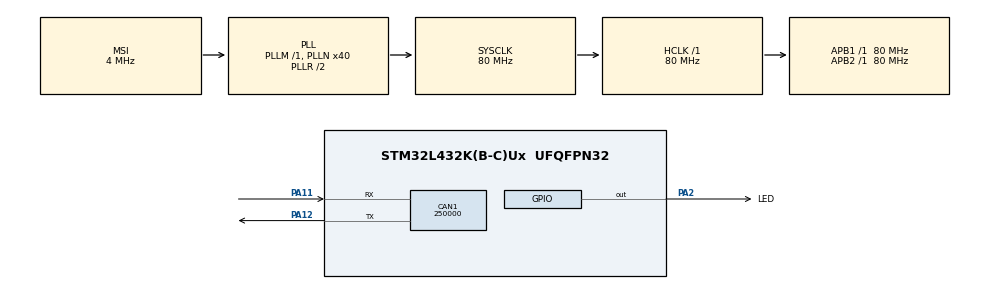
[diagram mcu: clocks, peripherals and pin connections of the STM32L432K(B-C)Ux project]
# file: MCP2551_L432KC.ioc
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CAN1.BS1=CAN_BS1_13TQ
CAN1.BS2=CAN_BS2_6TQ
CAN1.CalculateBaudRate=250000
CAN1.CalculateTimeBit=4000
CAN1.CalculateTimeQuantum=200.0
Mcu.Family=STM32L4
Mcu.Name=STM32L432K(B-C)Ux
Mcu.Package=UFQFPN32
NVIC.CAN1_RX0_IRQn=true\:0\:0\:false\:false\:true\:true\:true\:true
NVIC.PriorityGroup=NVIC_PRIORITYGROUP_4
PA0.Mode=HSE-External-Clock-Source-for-LittleOrca
PA0.Signal=RCC_CK_IN
PA11.Mode=CAN_Activate
PA11.Signal=CAN1_RX
PA12.Mode=CAN_Activate
PA12.Signal=CAN1_TX
PA13\ (JTMS-SWDIO).Mode=Serial_Wire
PA13\ (JTMS-SWDIO).Signal=SYS_JTMS-SWDIO
PA14\ (JTCK-SWCLK).Mode=Serial_Wire
PA14\ (JTCK-SWCLK).Signal=SYS_JTCK-SWCLK
PA2.GPIO_Label=LED
PA2.Signal=GPIO_Output
ProjectManager.HeapSize=0x200
ProjectManager.StackSize=0x400
ProjectManager.TargetToolchain=STM32CubeIDE
RCC.AHBFreq_Value=80000000
RCC.APB1Freq_Value=80000000
RCC.APB1TimFreq_Value=80000000
RCC.APB2Freq_Value=80000000
RCC.APB2TimFreq_Value=80000000
RCC.CortexFreq_Value=80000000
RCC.HCLKFreq_Value=80000000
RCC.HSE_VALUE=8000000
RCC.HSI48_VALUE=48000000
RCC.HSI_VALUE=16000000
RCC.LSE_VALUE=32768
RCC.MSI_VALUE=4000000
RCC.PLLN=40
RCC.SYSCLKFreq_VALUE=80000000
RCC.SYSCLKSource=RCC_SYSCLKSOURCE_PLLCLK
RCC.VCOOutputFreq_Value=160000000
board=custom

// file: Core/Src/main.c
/* USER CODE BEGIN Header */
/**
  ******************************************************************************
  * @file           : main.c
  * @brief          : Main program body
  ******************************************************************************
  * @attention
  *
  * Copyright (c) 2024 STMicroelectronics.
  * All rights reserved.
  *
  * This software is licensed under terms that can be found in the LICENSE file
  * in the root directory of this software component.
  * If no LICENSE file comes with this software, it is provided AS-IS.
  *
  ******************************************************************************
  */
/* USER CODE END Header */
#include "main.h"

CAN_HandleTypeDef hcan1;

/* USER CODE BEGIN PV */
CAN_TxHeaderTypeDef   TxHeader; // CAN Header
uint8_t               TxData[8]; // CAN Data
uint32_t              TxMailbox; // track id Transmission mailbox

CAN_RxHeaderTypeDef   RxHeader;
uint8_t               RxData[8];
uint8_t data_avail;

/* USER CODE END PV */

void SystemClock_Config(void);
static void MX_GPIO_Init(void);
static void MX_CAN1_Init(void);

/* USER CODE BEGIN 0 */
void HAL_CAN_RxFifo0MsgPendingCallback(CAN_HandleTypeDef *hcan1)
{
  if (HAL_CAN_GetRxMessage(hcan1, CAN_RX_FIFO0, &RxHeader, RxData) != HAL_OK) // read incoming message and put them in the RXBuffer
  {
    Error_Handler();
  }
  data_avail = 1;
}

/* USER CODE END 0 */

int main(void)
{

  /* MCU Configuration--------------------------------------------------------*/

  /* Reset of all peripherals, Initializes the Flash interface and the Systick. */
  HAL_Init();

  /* Configure the system clock */
  SystemClock_Config();

  /* Initialize all configured peripherals */
  MX_GPIO_Init();
  MX_CAN1_Init();
  /* USER CODE BEGIN 2 */
  TxHeader.IDE = CAN_ID_STD;
  TxHeader.StdId = 0x432;
  TxHeader.RTR = CAN_RTR_DATA;
  TxHeader.DLC = 2;

  TxData[0] = 0x01;
  TxData[1] = 0x02;
  data_avail = 0;

  CAN_FilterTypeDef can_filter;
  can_filter.FilterActivation = ENABLE;
  can_filter.FilterBank = 0;							// you can set many filters, for this we use bank no. 1
  can_filter.FilterFIFOAssignment = CAN_FILTER_FIFO0;  	// queue where we are going to read messages (CAN1 RX0 Interrupt)
  can_filter.FilterIdHigh = 0x0000;						// Other device ID first 32 bits
  can_filter.FilterIdLow = 0x0000;						// Other device ID last 32 bits
  can_filter.FilterMaskIdHigh = 0x0000;					// Mask for id (MSB) - which part of the id to be masked for id filtering
  can_filter.FilterMaskIdLow = 0x0000;					// Mask for id (LSB) -
  can_filter.FilterMode = CAN_FILTERMODE_IDMASK;		// Checks the received ID by applying the mask
  can_filter.FilterScale = CAN_FILTERSCALE_32BIT;		// Sets the filer length
  can_filter.SlaveStartFilterBank = 14;					// this parameters matters just when you have multiple CAN peripherals

  if (HAL_CAN_ConfigFilter(&hcan1, &can_filter) != HAL_OK)
  {
      Error_Handler();
  }

  HAL_CAN_Start(&hcan1);
  if (HAL_CAN_ActivateNotification(&hcan1, CAN_IT_RX_FIFO0_MSG_PENDING) != HAL_OK) // activate CAN interrupt Callback to receive message
  {
	  Error_Handler();
  }
  HAL_GPIO_WritePin(LED_GPIO_Port, LED_Pin, GPIO_PIN_SET);

  /* USER CODE END 2 */

  /* Infinite loop */
  while (1)
  {
	  if(data_avail){
		  HAL_GPIO_WritePin(LED_GPIO_Port, LED_Pin, GPIO_PIN_SET);
		  data_avail = 0;

		  HAL_Delay(2500);
		  if (HAL_CAN_AddTxMessage(&hcan1, &TxHeader, TxData, &TxMailbox) != HAL_OK) // send message through CAN
		  	  {
		  	     Error_Handler ();
		  	  }
	  }
	  else {
		  HAL_GPIO_WritePin(LED_GPIO_Port, LED_Pin, GPIO_PIN_RESET);
	  }

  }
}

void SystemClock_Config(void)
{
  RCC_OscInitTypeDef RCC_OscInitStruct = {0};
  RCC_ClkInitTypeDef RCC_ClkInitStruct = {0};

  /** Configure the main internal regulator output voltage
  */
  if (HAL_PWREx_ControlVoltageScaling(PWR_REGULATOR_VOLTAGE_SCALE1) != HAL_OK)
  {
    Error_Handler();
  }

  /** Initializes the RCC Oscillators according to the specified parameters
  * in the RCC_OscInitTypeDef structure.
  */
  RCC_OscInitStruct.OscillatorType = RCC_OSCILLATORTYPE_MSI;
  RCC_OscInitStruct.MSIState = RCC_MSI_ON;
  RCC_OscInitStruct.MSICalibrationValue = 0;
  RCC_OscInitStruct.MSIClockRange = RCC_MSIRANGE_6;
  RCC_OscInitStruct.PLL.PLLState = RCC_PLL_ON;
  RCC_OscInitStruct.PLL.PLLSource = RCC_PLLSOURCE_MSI;
  RCC_OscInitStruct.PLL.PLLM = 1;
  RCC_OscInitStruct.PLL.PLLN = 40;
  RCC_OscInitStruct.PLL.PLLP = RCC_PLLP_DIV7;
  RCC_OscInitStruct.PLL.PLLQ = RCC_PLLQ_DIV2;
  RCC_OscInitStruct.PLL.PLLR = RCC_PLLR_DIV2;
  if (HAL_RCC_OscConfig(&RCC_OscInitStruct) != HAL_OK)
  {
    Error_Handler();
  }

  /** Initializes the CPU, AHB and APB buses clocks
  */
  RCC_ClkInitStruct.ClockType = RCC_CLOCKTYPE_HCLK|RCC_CLOCKTYPE_SYSCLK
                              |RCC_CLOCKTYPE_PCLK1|RCC_CLOCKTYPE_PCLK2;
  RCC_ClkInitStruct.SYSCLKSource = RCC_SYSCLKSOURCE_PLLCLK;
  RCC_ClkInitStruct.AHBCLKDivider = RCC_SYSCLK_DIV1;
  RCC_ClkInitStruct.APB1CLKDivider = RCC_HCLK_DIV1;
  RCC_ClkInitStruct.APB2CLKDivider = RCC_HCLK_DIV1;

  if (HAL_RCC_ClockConfig(&RCC_ClkInitStruct, FLASH_LATENCY_4) != HAL_OK)
  {
    Error_Handler();
  }
}

static void MX_CAN1_Init(void)
{

  hcan1.Instance = CAN1;
  hcan1.Init.Prescaler = 16;
  hcan1.Init.Mode = CAN_MODE_NORMAL;
  hcan1.Init.SyncJumpWidth = CAN_SJW_1TQ;
  hcan1.Init.TimeSeg1 = CAN_BS1_13TQ;
  hcan1.Init.TimeSeg2 = CAN_BS2_6TQ;
  hcan1.Init.TimeTriggeredMode = DISABLE;
  hcan1.Init.AutoBusOff = DISABLE;
  hcan1.Init.AutoWakeUp = DISABLE;
  hcan1.Init.AutoRetransmission = DISABLE;
  hcan1.Init.ReceiveFifoLocked = DISABLE;
  hcan1.Init.TransmitFifoPriority = DISABLE;
  if (HAL_CAN_Init(&hcan1) != HAL_OK)
  {
    Error_Handler();
  }

}

static void MX_GPIO_Init(void)
{
  GPIO_InitTypeDef GPIO_InitStruct = {0};

  /* GPIO Ports Clock Enable */
  __HAL_RCC_GPIOA_CLK_ENABLE();

  /*Configure GPIO pin Output Level */
  HAL_GPIO_WritePin(LED_GPIO_Port, LED_Pin, GPIO_PIN_RESET);

  /*Configure GPIO pin : LED_Pin */
  GPIO_InitStruct.Pin = LED_Pin;
  GPIO_InitStruct.Mode = GPIO_MODE_OUTPUT_PP;
  GPIO_InitStruct.Pull = GPIO_NOPULL;
  GPIO_InitStruct.Speed = GPIO_SPEED_FREQ_LOW;
  HAL_GPIO_Init(LED_GPIO_Port, &GPIO_InitStruct);

}

void Error_Handler(void)
{
  __disable_irq();
  while (1)
  {
  }
}
